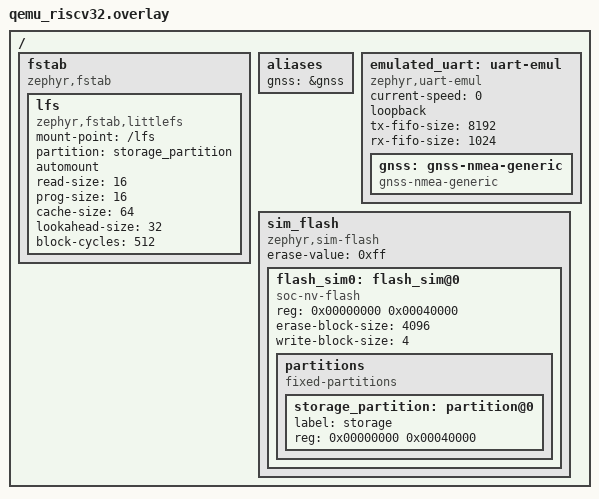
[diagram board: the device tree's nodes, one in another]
/ {
	fstab {
		compatible = "zephyr,fstab";

		lfs: lfs {
			compatible = "zephyr,fstab,littlefs";
			mount-point = "/lfs";
			partition = <&storage_partition>;
			automount;
			read-size = <16>;
			prog-size = <16>;
			cache-size = <64>;
			lookahead-size = <32>;
			block-cycles = <512>;
		};
	};

	aliases {
		gnss = &gnss;
	};

	emulated_uart: uart-emul {
		compatible = "zephyr,uart-emul";
		current-speed = <0>;
		loopback;
		tx-fifo-size = <8192>;
		rx-fifo-size = <1024>;

		gnss: gnss-nmea-generic {
			compatible = "gnss-nmea-generic";
		};
	};

	sim_flash: sim_flash {
		compatible = "zephyr,sim-flash";
		#address-cells = <1>;
		#size-cells = <1>;
		erase-value = <0xff>;

		flash_sim0: flash_sim@0 {
			compatible = "soc-nv-flash";
			reg = <0x00000000 0x00040000>;

			erase-block-size = <4096>;
			write-block-size = <4>;

			partitions {
				compatible = "fixed-partitions";
				#address-cells = <1>;
				#size-cells = <1>;

				storage_partition: partition@0 {
					label = "storage";
					reg = <0x00000000 0x00040000>;
				};
			};
		};
	};
};
